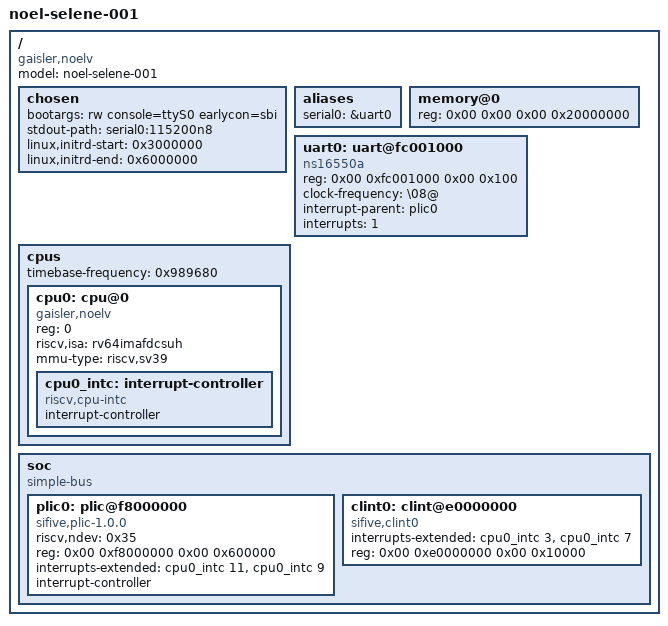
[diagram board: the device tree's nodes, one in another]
/dts-v1/;

/ {
	#address-cells = <2>;
	#size-cells = <2>;
	model = "noel-selene-001";
	compatible = "gaisler,noelv";

	chosen {
		bootargs = "rw console=ttyS0 earlycon=sbi";
		stdout-path = "serial0:115200n8";
		linux,initrd-start = <0x3000000>;
		linux,initrd-end = <0x6000000>;
	};

	aliases {
		serial0 = &uart0;
	};

	memory@0 {
		device_type = "memory";
		/* Only take 512 MiB */
		reg = <0x00 0x00 0x00 0x20000000>;
	};

	uart0: uart@fc001000 {
		compatible = "ns16550a";
		reg = <0x00 0xfc001000 0x00 0x100>;
		clock-frequency = "\08@";
		interrupt-parent = <&plic0>;
		interrupts = <1>;
	};

	cpus {
		#address-cells = <1>;
		#size-cells = <0>;
		timebase-frequency = <0x989680>;

		cpu0: cpu@0 {
			device_type = "cpu";
			reg = <0>;
			status = "okay";
			compatible = "gaisler,noelv", "riscv";
			riscv,isa = "rv64imafdcsuh";
			mmu-type = "riscv,sv39";

			cpu0_intc: interrupt-controller {
				#address-cells = <0>;
				#interrupt-cells = <1>;
				interrupt-controller;
				compatible = "riscv,cpu-intc";
			};
		};
	};

	soc {
		#address-cells = <2>;
		#size-cells = <2>;
		compatible = "simple-bus";
		ranges;

		plic0: plic@f8000000 {
			riscv,ndev = <0x35>;
			reg = <0x00 0xf8000000 0x00 0x600000>;
			interrupts-extended = <
				&cpu0_intc 11
				&cpu0_intc 9
			>;
			interrupt-controller;
			compatible = "sifive,plic-1.0.0\0riscv,plic0";
			#interrupt-cells = <0x01>;
			#address-cells = <0x00>;
		};

		clint0: clint@e0000000 {
			interrupts-extended = <
				&cpu0_intc 3 
				&cpu0_intc 7
			>;
			reg = <0x00 0xe0000000 0x00 0x10000>;
			compatible = "sifive,clint0\0riscv,clint0";
		};
	};
};
